# MDR32F8 register map
Vendor: Milandr; File version: 1.0
CPU: CM4 r1p1, little endian, no MPU, no FPU, 3 interrupt priority bits
Registers are 32-bit, read-write, reset 0x0 unless marked. A register's access mark holds for its fields unless they carry their own. Offsets are from the block's base; [hi:lo] are bit positions; {n}, {i} and the like mark numbered series; 'fields as' and 'values as' point back to an identical list.

## FT_CNTR — Fault Tolerance Control
Base 0x40003000
0x00 KEY — Key lock Register
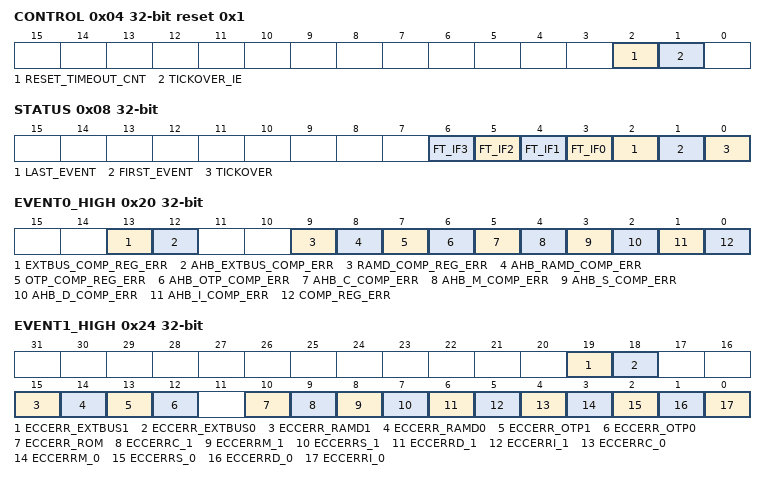
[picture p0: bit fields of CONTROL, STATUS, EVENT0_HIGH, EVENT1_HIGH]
0x04 CONTROL reset 0x1
  [2] RESET_TIMEOUT_CNT — Reset register TIMEOUTCNT
  [1] TICKOVER_IE — Enable IQR on TICKOVER
0x08 STATUS
  [n+3] FT_IF{n} (n=0..3), [2] LAST_EVENT, [1] FIRST_EVENT, [0] TICKOVER
0x0C TIMEOUT 16-bit reset 0xFFFF
0x10 TICKCNT
0x14 FIRSTEVENT
0x18 LASTEVENT
0x1C TIMEOUTCNT reset 0x1FFFF
  [16:0] TIMEOUTCNT
0x20 EVENT0_HIGH
  [13] EXTBUS_COMP_REG_ERR, [12] AHB_EXTBUS_COMP_ERR, [9] RAMD_COMP_REG_ERR, [8] AHB_RAMD_COMP_ERR, [7] OTP_COMP_REG_ERR, [6] AHB_OTP_COMP_ERR, [5] AHB_C_COMP_ERR, [4] AHB_M_COMP_ERR, [3] AHB_S_COMP_ERR, [2] AHB_D_COMP_ERR, [1] AHB_I_COMP_ERR, [0] COMP_REG_ERR
0x24 EVENT1_HIGH
  [19] ECCERR_EXTBUS1, [18] ECCERR_EXTBUS0, [15] ECCERR_RAMD1, [14] ECCERR_RAMD0, [13] ECCERR_OTP1, [12] ECCERR_OTP0, [10] ECCERR_ROM, [9] ECCERRC_1, [8] ECCERRM_1, [7] ECCERRS_1, [6] ECCERRD_1, [5] ECCERRI_1, [4] ECCERRC_0, [3] ECCERRM_0, [2] ECCERRS_0, [1] ECCERRD_0, [0] ECCERRI_0
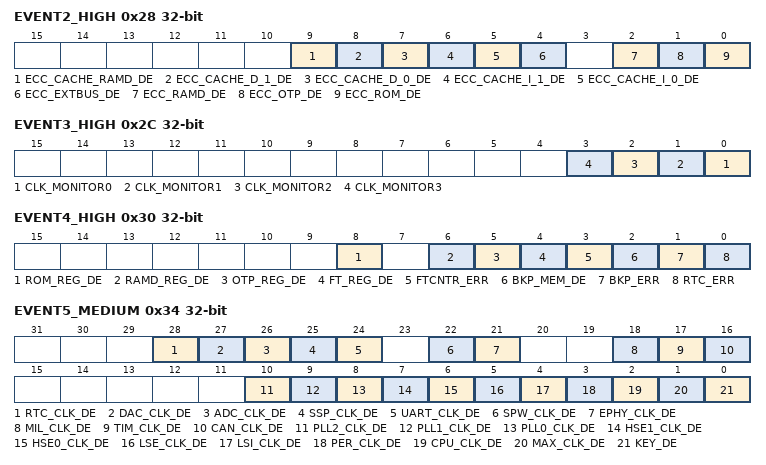
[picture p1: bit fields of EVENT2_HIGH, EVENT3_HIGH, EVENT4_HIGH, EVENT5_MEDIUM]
0x28 EVENT2_HIGH
  [9] ECC_CACHE_RAMD_DE, [8] ECC_CACHE_D_1_DE, [7] ECC_CACHE_D_0_DE, [6] ECC_CACHE_I_1_DE, [5] ECC_CACHE_I_0_DE, [4] ECC_EXTBUS_DE, [2] ECC_RAMD_DE, [1] ECC_OTP_DE, [0] ECC_ROM_DE
0x2C EVENT3_HIGH
  [n] CLK_MONITOR{n} (n=0..3)
0x30 EVENT4_HIGH
  [8] ROM_REG_DE, [6] RAMD_REG_DE, [5] OTP_REG_DE, [4] FT_REG_DE, [3] FTCNTR_ERR, [2] BKP_MEM_DE, [1] BKP_ERR, [0] RTC_ERR
0x34 EVENT5_MEDIUM
  [28] RTC_CLK_DE, [27] DAC_CLK_DE, [26] ADC_CLK_DE, [25] SSP_CLK_DE, [24] UART_CLK_DE, [22] SPW_CLK_DE, [21] EPHY_CLK_DE, [18] MIL_CLK_DE, [17] TIM_CLK_DE, [16] CAN_CLK_DE, [10] PLL2_CLK_DE, [9] PLL1_CLK_DE, [8] PLL0_CLK_DE, [7] HSE1_CLK_DE, [6] HSE0_CLK_DE, [5] LSE_CLK_DE, [4] LSI_CLK_DE, [3] PER_CLK_DE, [2] CPU_CLK_DE, [1] MAX_CLK_DE, [0] KEY_DE
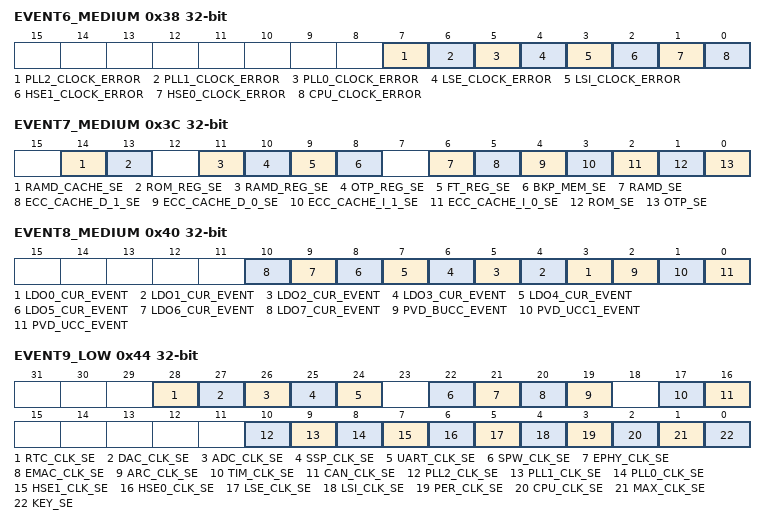
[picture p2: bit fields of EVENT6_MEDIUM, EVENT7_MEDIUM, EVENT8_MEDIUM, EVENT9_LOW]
0x38 EVENT6_MEDIUM
  [7] PLL2_CLOCK_ERROR, [6] PLL1_CLOCK_ERROR, [5] PLL0_CLOCK_ERROR, [4] LSE_CLOCK_ERROR, [3] LSI_CLOCK_ERROR, [2] HSE1_CLOCK_ERROR, [1] HSE0_CLOCK_ERROR, [0] CPU_CLOCK_ERROR
0x3C EVENT7_MEDIUM
  [14] RAMD_CACHE_SE, [13] ROM_REG_SE, [11] RAMD_REG_SE, [10] OTP_REG_SE, [9] FT_REG_SE, [8] BKP_MEM_SE, [6] RAMD_SE, [5] ECC_CACHE_D_1_SE, [4] ECC_CACHE_D_0_SE, [3] ECC_CACHE_I_1_SE, [2] ECC_CACHE_I_0_SE, [1] ROM_SE, [0] OTP_SE
0x40 EVENT8_MEDIUM
  [n+3] LDO{n}_CUR_EVENT (n=0..7), [2] PVD_BUCC_EVENT, [1] PVD_UCC1_EVENT, [0] PVD_UCC_EVENT
0x44 EVENT9_LOW
  [28] RTC_CLK_SE, [27] DAC_CLK_SE, [26] ADC_CLK_SE, [25] SSP_CLK_SE, [24] UART_CLK_SE, [22] SPW_CLK_SE, [21] EPHY_CLK_SE, [20] EMAC_CLK_SE, [19] ARC_CLK_SE, [17] TIM_CLK_SE, [16] CAN_CLK_SE, [10] PLL2_CLK_SE, [9] PLL1_CLK_SE, [8] PLL0_CLK_SE, [7] HSE1_CLK_SE, [6] HSE0_CLK_SE, [5] LSE_CLK_SE, [4] LSI_CLK_SE, [3] PER_CLK_SE, [2] CPU_CLK_SE, [1] MAX_CLK_SE, [0] KEY_SE
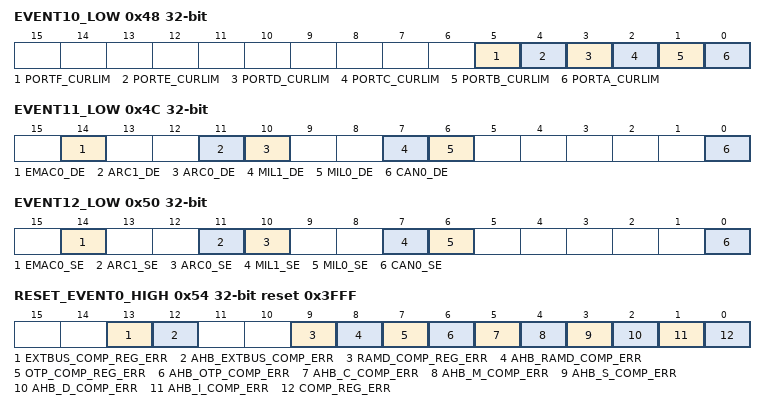
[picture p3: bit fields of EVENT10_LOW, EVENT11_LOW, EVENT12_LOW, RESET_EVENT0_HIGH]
0x48 EVENT10_LOW
  [5] PORTF_CURLIM, [4] PORTE_CURLIM, [3] PORTD_CURLIM, [2] PORTC_CURLIM, [1] PORTB_CURLIM, [0] PORTA_CURLIM
0x4C EVENT11_LOW
  [14] EMAC0_DE, [11] ARC1_DE, [10] ARC0_DE, [7] MIL1_DE, [6] MIL0_DE, [0] CAN0_DE
0x50 EVENT12_LOW
  [14] EMAC0_SE, [11] ARC1_SE, [10] ARC0_SE, [7] MIL1_SE, [6] MIL0_SE, [0] CAN0_SE
0x54 RESET_EVENT0_HIGH reset 0x3FFF
  fields as EVENT0_HIGH
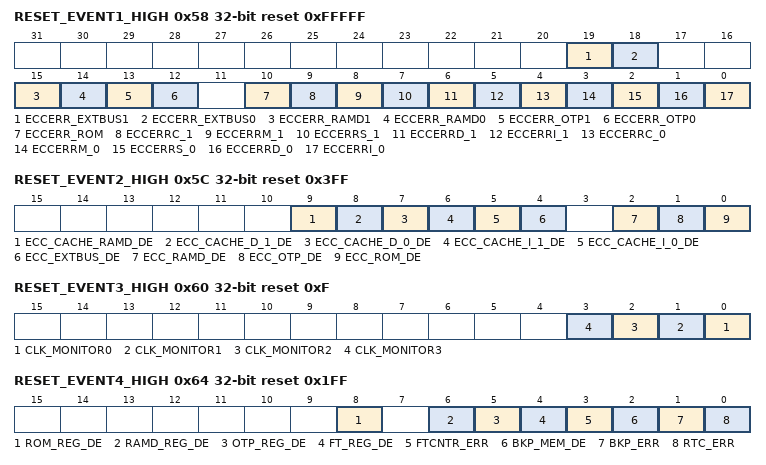
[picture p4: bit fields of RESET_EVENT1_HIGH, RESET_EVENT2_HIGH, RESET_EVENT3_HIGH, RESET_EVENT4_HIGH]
0x58 RESET_EVENT1_HIGH reset 0xFFFFF
  fields as EVENT1_HIGH
0x5C RESET_EVENT2_HIGH reset 0x3FF
  fields as EVENT2_HIGH
0x60 RESET_EVENT3_HIGH reset 0xF
  [n] CLK_MONITOR{n} (n=0..3)
0x64 RESET_EVENT4_HIGH reset 0x1FF
  fields as EVENT4_HIGH
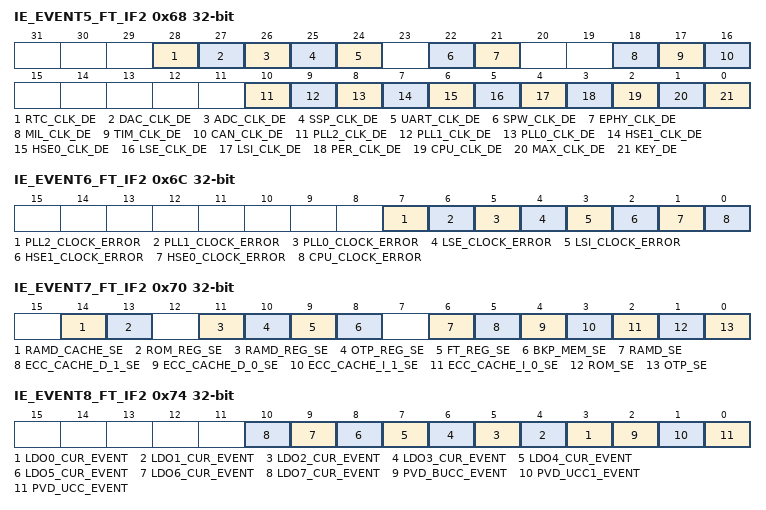
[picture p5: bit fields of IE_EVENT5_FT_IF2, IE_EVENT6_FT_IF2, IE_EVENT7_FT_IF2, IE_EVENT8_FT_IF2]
0x68 IE_EVENT5_FT_IF2
  fields as EVENT5_MEDIUM
0x6C IE_EVENT6_FT_IF2
  fields as EVENT6_MEDIUM
0x70 IE_EVENT7_FT_IF2
  fields as EVENT7_MEDIUM
0x74 IE_EVENT8_FT_IF2
  fields as EVENT8_MEDIUM
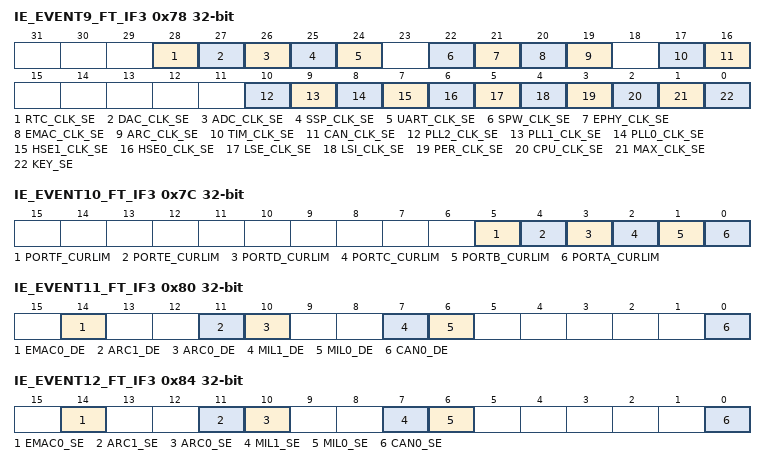
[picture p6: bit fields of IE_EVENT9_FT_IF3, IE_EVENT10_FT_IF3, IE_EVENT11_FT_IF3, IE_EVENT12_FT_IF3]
0x78 IE_EVENT9_FT_IF3
  fields as EVENT9_LOW
0x7C IE_EVENT10_FT_IF3
  fields as EVENT10_LOW
0x80 IE_EVENT11_FT_IF3
  fields as EVENT11_LOW
0x84 IE_EVENT12_FT_IF3
  fields as EVENT12_LOW
